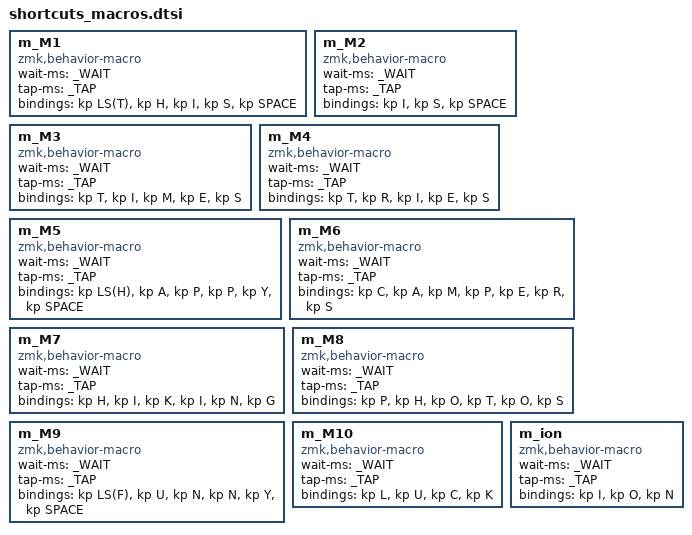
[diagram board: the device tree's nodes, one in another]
#include <dt-bindings/zmk/keys.h>

/* ************************************************** */
/* TEST macros to futz with settings in batches and string helpers
    tries with Shift and with Punctuation and spaces...
    [ ] does separating keys inside bindings= expression matter?
    
    2024-04-16 removed label properties; deprecated in ZMK v3
*/

#define _WAIT <5>
#define _TAP <5>

m_M1: m_M1 {
    wait-ms = _WAIT;
    tap-ms = _TAP;
    compatible = "zmk,behavior-macro";
    #binding-cells = <0>;
    bindings = <&kp LS(T) &kp H &kp I &kp S &kp SPACE>;
};

m_M2: m_M2 {
    wait-ms = _WAIT;
    tap-ms = _TAP;
    compatible = "zmk,behavior-macro";
    #binding-cells = <0>;
    bindings = <&kp I>, <&kp S>, <&kp SPACE>;
};

m_M3: m_M3 {
    wait-ms = _WAIT;
    tap-ms = _TAP;
    compatible = "zmk,behavior-macro";
    #binding-cells = <0>;
    bindings = <&kp T &kp I &kp M &kp E &kp S>;
};

m_M4: m_M4 {
    wait-ms = _WAIT;
    tap-ms = _TAP;
    compatible = "zmk,behavior-macro";
    #binding-cells = <0>;
    bindings = <&kp T &kp R &kp I &kp E &kp S>;
};

m_M5: m_M5 {
    wait-ms = _WAIT;
    tap-ms = _TAP;
    compatible = "zmk,behavior-macro";
    #binding-cells = <0>;
    bindings = <&kp LS(H) &kp A &kp P &kp P &kp Y &kp SPACE>;
};

m_M6: m_M6 {
    wait-ms = _WAIT;
    tap-ms = _TAP;
    compatible = "zmk,behavior-macro";
    #binding-cells = <0>;
    bindings = <&kp C &kp A &kp M &kp P &kp E &kp R &kp S>;
};

m_M7: m_M7 {
    wait-ms = _WAIT;
    tap-ms = _TAP;
    compatible = "zmk,behavior-macro";
    #binding-cells = <0>;
    bindings = <&kp H &kp I &kp K &kp I &kp N &kp G>;
};

m_M8: m_M8 {
    wait-ms = _WAIT;
    tap-ms = _TAP;
    compatible = "zmk,behavior-macro";
    #binding-cells = <0>;
    bindings = <&kp P &kp H &kp O &kp T &kp O &kp S>;
};

m_M9: m_M9 {
    wait-ms = _WAIT;
    tap-ms = _TAP;
    compatible = "zmk,behavior-macro";
    #binding-cells = <0>;
    bindings = <&kp LS(F) &kp U &kp N &kp N &kp Y &kp SPACE>;
};

m_M10: m_M10 {
    wait-ms = _WAIT;
    tap-ms = _TAP;
    compatible = "zmk,behavior-macro";
    #binding-cells = <0>;
    bindings = <&kp L &kp U &kp C &kp K>;
};

m_ion: m_ion {
    wait-ms = _WAIT;
    tap-ms = _TAP;
    compatible = "zmk,behavior-macro";
    #binding-cells = <0>;
    bindings = <&kp I &kp O &kp N>;
};


